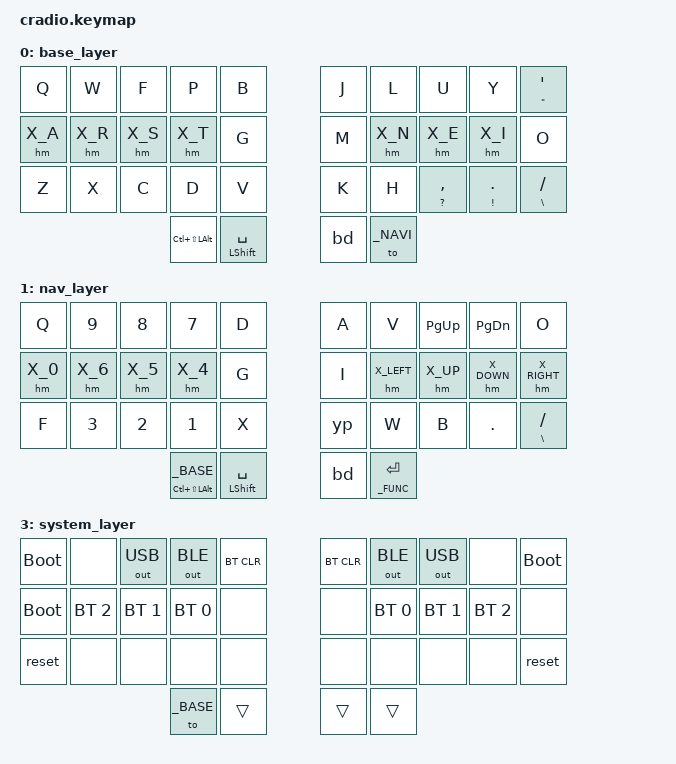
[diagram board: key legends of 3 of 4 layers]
/*
 * Copyright (c) 2020 The ZMK Contributors
 *
 * SPDX-License-Identifier: MIT
 */

#include <behaviors.dtsi>
#include <dt-bindings/zmk/keys.h>
#include <dt-bindings/zmk/bt.h>
#include <dt-bindings/zmk/outputs.h>
#include "key_var.h"

&lt {
    tapping-term-ms = <130>;
    flavor = "tap-preferred";
};

&sk {
     release-after-ms = <300>;
};

/ {
    behaviors {
        hm: homerow_mods {
            compatible = "zmk,behavior-hold-tap";
            label = "HOMEROW_MODS";
            #binding-cells = <2>;
            tapping-term-ms = <300>;
            quick_tap_ms = <0>;
            flavor = "balanced";
            bindings = <&kp>, <&kp>;
        };
        lm: layer_mods {
            compatible = "zmk,behavior-hold-tap";
            label = "LAYER_MODS";
            #binding-cells = <2>;
            tapping-term-ms = <200>;
            quick_tap_ms = <0>;
            flavor = "balanced";
            bindings = <&to>, <&kp>;
        };
        ml: mod_layer {
            compatible = "zmk,behavior-hold-tap";
            label = "mod_layer";
            #binding-cells = <2>;
            tapping-term-ms = <200>;
            quick_tap_ms = <0>;
            flavor = "balanced";
            bindings = <&kp>, <&to>;
        };
        ss: sticky_shift {
            compatible = "zmk,behavior-hold-tap";
            label = "STICKY_SHIFT";
            #binding-cells = <2>;
            tapping-term-ms = <130>;
            quick_tap_ms = <0>;
            flavor = "tap-preferred";
            bindings = <&kp>, <&sk>;
        };
        bd: backspace_delete {
            compatible = "zmk,behavior-mod-morph";
            label = "BACKSPACE_DELETE";
            #binding-cells = <0>;
            bindings = <&kp BACKSPACE>, <&kp DELETE>;
            mods = <(MOD_LSFT|MOD_RSFT)>;
        };
            en: navi_enter {
            compatible = "zmk,behavior-mod-morph";
            label = "NAVI_ENTER";
            #binding-cells = <0>;
            bindings = <&to _NAVI>, <&kp ENTER>;
            mods = <(MOD_LSFT|MOD_RSFT)>;
        };
            ef: func_enter {
            compatible = "zmk,behavior-mod-morph";
            label = "FUNC_ENTER";
            #binding-cells = <0>;
            bindings = <&to _FUNC>, <&kp ENTER>;
            mods = <(MOD_LSFT|MOD_RSFT)>;
        };
            yp: y_p {
            compatible = "zmk,behavior-mod-morph";
            label = "Y_P";
            #binding-cells = <0>;
            bindings = <&kp Y>, <&kp P>;
            mods = <(MOD_LSFT|MOD_RSFT)>;
        };
        bm: backspace_mod {
            compatible = "zmk,behavior-hold-tap";
            label = "BACKSPACE_MOD";
            #binding-cells = <2>;
            tapping-term-ms = <300>;
            quick_tap_ms = <0>;
            flavor = "tap-preferred";
            bindings = <&to>, <&bd>;
        };
    };

    combos {
        #include "combos.dtsi"
    };

    keymap {
        compatible = "zmk,keymap";

        base_layer {
                        bindings = <
    &kp Q       &kp W       &kp F       &kp P       &kp B              &kp J       &kp L       &kp U       &kp Y       &mt DQT SQT 
    &hm X_A     &hm X_R     &hm X_S     &hm X_T     &kp G              &kp M       &hm X_N     &hm X_E     &hm X_I     &kp O   
    &kp Z       &kp X       &kp C       &kp D       &kp V              &kp K       &kp H       &mt QMARK COMMA    &mt EXCL DOT     &mt BSLH FSLH
                                        &kp LC(LS(LALT)) &hm LSHIFT SPACE    &bd         &to _NAVI
                        >;
                };
        nav_layer {
                        bindings = <
    &kp Q     &kp N9    &kp N8      &kp N7     &kp D          &kp A &kp V   &kp PAGE_UP &kp PAGE_DOWN  &kp O     
    &hm X_0  &hm X_6    &hm X_5    &hm X_4   &kp G            &kp I &hm X_LEFT &hm X_UP &hm X_DOWN  &hm X_RIGHT  
    &kp F  &kp N3   &kp N2  &kp N1  &kp X                   &yp  &kp W  &kp B    &kp DOT  &mt BSLH FSLH
                            &ml LC(LS(LALT)) _BASE       &hm LSHIFT SPACE           &bd       &lm _FUNC ENTER
                        >;
                };
        function_layer {
                        bindings = <
    &kp F12       &kp F9       &kp F8       &kp F7       &none              &none       &kp C_PP      &kp C_NEXT      &kp C_PREV     &kp C_POWER
    &kp F11    &kp F6    &kp F5   &kp F4     &to _SYST       &kp C_MUTE      &kp C_VOLUME_UP      &kp C_VOLUME_DOWN      &none
    &kp F10       &kp F3       &kp F2       &kp F1       &none         &none       &none      &kp C_BRI_INC      &kp C_BRI_DEC      &none
                                        &ml LC(LS(LALT)) _BASE      &to _BASE             &to _BASE   &to _BASE
                        >;
                };
        system_layer {
                        bindings = <
    &bootloader     &none           &out OUT_USB    &out OUT_BLE        &bt BT_CLR         &bt BT_CLR       &out OUT_BLE    &out OUT_USB    &none           &bootloader
    &bootloader           &bt BT_SEL 2    &bt BT_SEL 1    &bt BT_SEL 0        &none              &none            &bt BT_SEL 0    &bt BT_SEL 1    &bt BT_SEL 2    &none
    &reset          &none           &none           &none               &none              &none            &none           &none           &none           &reset
                                                   &to _BASE              &trans             &trans           &trans
                        >;
                };
        };
};
